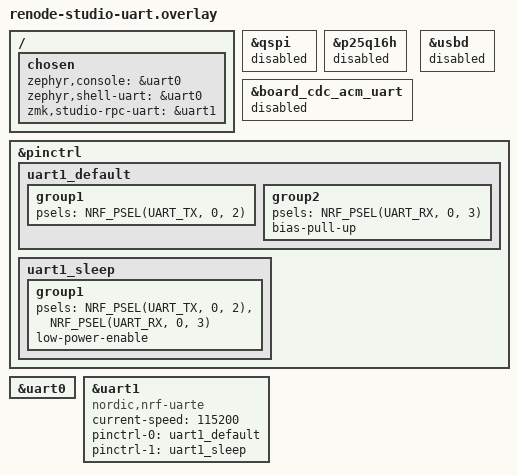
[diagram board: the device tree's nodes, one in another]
/* Renode-only UART transport for the XIAO nRF52840. Do not flash this build. */

&qspi {
    status = "disabled";
};

&p25q16h {
    status = "disabled";
};

&board_cdc_acm_uart {
    status = "disabled";
};

&usbd {
    status = "disabled";
};

&pinctrl {
    uart1_default: uart1_default {
        group1 {
            psels = <NRF_PSEL(UART_TX, 0, 2)>;
        };
        group2 {
            psels = <NRF_PSEL(UART_RX, 0, 3)>;
            bias-pull-up;
        };
    };

    uart1_sleep: uart1_sleep {
        group1 {
            psels = <NRF_PSEL(UART_TX, 0, 2)>,
                    <NRF_PSEL(UART_RX, 0, 3)>;
            low-power-enable;
        };
    };
};

&uart0 {
    status = "okay";
};

&uart1 {
    compatible = "nordic,nrf-uarte";
    status = "okay";
    current-speed = <115200>;
    pinctrl-0 = <&uart1_default>;
    pinctrl-1 = <&uart1_sleep>;
    pinctrl-names = "default", "sleep";
};

/ {
    chosen {
        zephyr,console = &uart0;
        zephyr,shell-uart = &uart0;
        zmk,studio-rpc-uart = &uart1;
    };
};
